AUTOSAR XML (schema 00044)
package /E40_Platform_System_SystemPackage/Components
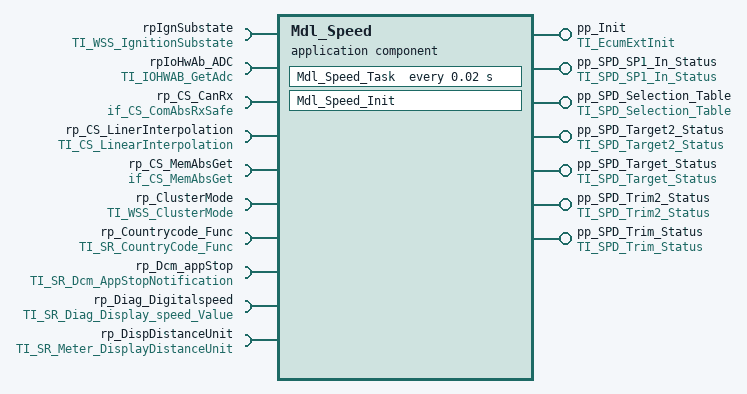
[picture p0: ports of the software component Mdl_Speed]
  application sw component type Mdl_Speed
    7 x provide port:
      pp_Init: server-com-spec{operation=Init, queue-length=1}, provided-interface=TI_EcumExtInit
      pp_SPD_SP1_In_Status: nonqueued-sender-com-spec{data-element=SP1_In_Status, init-value=constant-reference=Mdl_SpeedSP1_In_StatusValue0}, provided-interface=TI_SPD_SP1_In_Status
      pp_SPD_Selection_Table: nonqueued-sender-com-spec{data-element=Speed_Selection_Table, init-value=constant-reference=Mdl_SpeedSpeed_Selection_TableValue0}, provided-interface=TI_SPD_Selection_Table
      pp_SPD_Target2_Status: nonqueued-sender-com-spec{data-element=Spd_Target2_Status, init-value=constant-reference=Mdl_SpeedSpd_Target2_StatusValue0}, provided-interface=TI_SPD_Target2_Status
      pp_SPD_Target_Status: nonqueued-sender-com-spec{data-element=Spd_Target_Status, init-value=constant-reference=Mdl_SpeedSpd_Target_StatusValue0}, provided-interface=TI_SPD_Target_Status
      pp_SPD_Trim2_Status: nonqueued-sender-com-spec{data-element=Spd_Trim2_Status, init-value=constant-reference=Mdl_SpeedSpd_Trim2_StatusValue0}, provided-interface=TI_SPD_Trim2_Status
      pp_SPD_Trim_Status: nonqueued-sender-com-spec{data-element=Spd_Trim_Status, init-value=constant-reference=Mdl_SpeedSpd_Trim_StatusValue0}, provided-interface=TI_SPD_Trim_Status
    10 x require port:
      rpIgnSubstate: nonqueued-receiver-com-spec{data-element=IgnitionSubstate, init-value=constant-reference=Mdl_SpeedIgnitionSubstateValue0}, required-interface=TI_WSS_IgnitionSubstate
      rpIoHwAb_ADC: required-com-specs=[GetAsyncRawAdc, GetProcessedAdc, GetSyncRawAdc], required-interface=TI_IOHWAB_GetAdc
      rp_CS_CanRx: required-interface=if_CS_ComAbsRxSafe
        required-com-specs:
          RxCan_GetSignalValue
          RxCan_GetSignalValueU8Arr
          RxCan_SetSignalInitValue
          RxCan_SetSignalInitValueU8Arr
          RxCan_SignalClearJustRcvdStatus
          RxCan_SignalGetJustRcvdStatus
          RxCan_SignalInvalidProcessingControl
          RxCan_SignalMissingProcessingControl
          RxCan_SignalNRProcessingControl
      rp_CS_LinerInterpolation: required-interface=TI_CS_LinearInterpolation
        required-com-specs:
          Get_LinearInterpolateByte
          Get_LinearInterpolateSByte
          Get_LinearInterpolateSWord
          Get_LinearInterpolateWord
      rp_CS_MemAbsGet: required-interface=if_CS_MemAbsGet
        required-com-specs:
          Get_BsConst_Audio_Element
          Get_BsConst_Communication_Element
          Get_BsConst_EngOffTimer_Element
          Get_BsConst_FuelGauge_Element
          Get_BsConst_OilGauge_Element
          Get_BsConst_PowerGauge_Element
          Get_BsConst_Power_Element
          Get_BsConst_RealTimeClock_Element
          Get_BsConst_ServiceReminder_Element
          Get_BsConst_SpeedoGauge_Element
          Get_BsConst_TachoGauge_Element
          Get_BsConst_TempGauge_Element
          Get_BsConst_TripComputer_Element
          Get_BsConst_Warning_Element
          Get_BsCys_Certicificate_Element
          Get_BsDiag_Dtc_Element
          Get_BsDiag_ErrorRecord_Element
          Get_BsReten_Audio_Element
          Get_BsReten_Communication_Element
          Get_BsReten_Display_Element
          Get_BsReten_Gauges_Element
          Get_BsReten_Illumination_Element
          Get_BsReten_Odometer_Element
          Get_BsReten_Personalization_Element
          Get_BsReten_Power_Element
          Get_BsReten_RealTimeClock_Element
          Get_BsReten_Tripcomputer_Element
          Get_BsReten_Warning_Element
          Get_BsRt_CusDlt_Element
          Get_BsRt_FuelGauge_Element
          Get_BsRt_Illumination_Element
          Get_BsRt_Odometer_Element
          Get_BsRt_OilGauge_Element
          Get_BsRt_Personalization_Element
          Get_BsRt_PowerGauge_Element
          Get_BsRt_RealTimeClock_Element
          Get_BsRt_SpeedoGauge_Element
          Get_BsRt_TachoGauge_Element
          Get_BsRt_TempGauge_Element
          Get_BsRt_TripComputer_Element
          Get_BsRt_Warning_Element
          Get_BsShare_EcuPartNumber_Element
          Get_BsShare_SwUpdFotaFinPrint_Element
          Get_BsShare_SwUpdFotaMode_Element
          Get_BsShare_SwUpdFotaStatus_Element
          Get_BsShare_SwUpdFotadecrypt_Element
          Get_BsShare_SwUpdReflash_Element
          Get_BsShare_VehicleConfig_Element
          Get_BsShare_VisMeet_Element
          Get_RefCys_Certicificate1_Element
          Get_RefCys_Certicificate_Element
          Get_BsShare_VisMeet_EOLEntry_Element
          Get_BsShare_AssemblyManufacturingDate
          Get_BsShare_AssemblyPlantNumber
          Get_BsShare_HWModification
          Get_BsShare_PCBSerialNumber
          Get_BsShare_ProductSerialNumber
          Get_BsShare_SMTManufacturingDate
          Get_BsShare_SMTPlantNumber
          Get_BsShare_VisteonPCBPartNumber
          Get_BsShare_VisteonPartNumber
          Get_BsConst_Temperature_Sensor_Conv_SafeCopy2
          Get_BsConst_Temperature_Sensor_Conv_SafeCopy1
          Get_BsConst_Temperature_Sensor_Conv
          Get_BsConst_Temp_Threshold_Hysteresis_Derating_SafeCopy2
          Get_BsConst_Temp_Threshold_Hysteresis_Derating_SafeCopy1
          Get_BsConst_Temp_Threshold_Hysteresis_Derating
          Get_BsConst_PWM_boost_bypass_duty_SafeCopy2
          Get_BsConst_PWM_boost_bypass_duty_SafeCopy1
          Get_BsConst_PWM_boost_bypass_duty
          Get_BsConst_PCB_Temperature_Sensor_Conv_SafeCopy2
          Get_BsConst_PCB_Temperature_Sensor_Conv_SafeCopy1
          Get_BsConst_PCB_Temperature_Sensor_Conv
          Get_BsConst_Lookup_Curve_HotSpot_Coef_Y_SafeCopy2
          Get_BsConst_Lookup_Curve_HotSpot_Coef_Y_SafeCopy1
          Get_BsConst_Lookup_Curve_HotSpot_Coef_Y
          Get_BsConst_Lookup_Curve_HotSpot_Coef_X_SafeCopy2
          Get_BsConst_Lookup_Curve_HotSpot_Coef_X_SafeCopy1
          Get_BsConst_Lookup_Curve_HotSpot_Coef_X
          Get_BsConst_Display_Illum_Max_Level_SafeCopy2
          Get_BsConst_Display_Illum_Max_Level_SafeCopy1
          Get_BsConst_Display_Illum_Max_Level
          Get_BsConst_Derating_Backlight_Disable_SafeCopy2
          Get_BsConst_Derating_Backlight_Disable_SafeCopy1
          Get_BsConst_Derating_Backlight_Disable
          Get_BsConst_Compensation_Line_Slope_m_SafeCopy2
          Get_BsConst_Compensation_Line_Slope_m_SafeCopy1
          Get_BsConst_Compensation_Line_Slope_m
          Get_BsConst_Compensation_Line_Shift_b_SafeCopy2
          Get_BsConst_Compensation_Line_Shift_b_SafeCopy1
          Get_BsConst_Compensation_Line_Shift_b
          Get_BsConst_BsConst_Illumination_ReservedByte_SafeCopy2
          Get_BsConst_BsConst_Illumination_ReservedByte_SafeCopy1
          Get_BsConst_BsConst_Illumination_ReservedByte
      rp_ClusterMode: nonqueued-receiver-com-spec{data-element=WSSCurrentClusterMode, init-value=constant-reference=Mdl_SpeedWSSCurrentClusterModeValue0}, required-interface=TI_WSS_ClusterMode
      rp_Countrycode_Func: nonqueued-receiver-com-spec{data-element=CountryCode_Func, init-value=constant-reference=Mdl_SpeedCountryCode_FuncValue0}, required-interface=TI_SR_CountryCode_Func
      rp_Dcm_appStop: nonqueued-receiver-com-spec{data-element=AppId, init-value=constant-reference=Mdl_SpeedAppIdValue0}, required-interface=TI_SR_Dcm_AppStopNotification
      rp_Diag_Digitalspeed: nonqueued-receiver-com-spec{data-element=Diag_Digital_Speed_Value, init-value=constant-reference=Mdl_SpeedDiag_Digital_Speed_ValueValue0}, required-interface=TI_SR_Diag_Display_speed_Value
      rp_DispDistanceUnit: nonqueued-receiver-com-spec{data-element=DisplayUnit, init-value=constant-reference=Mdl_SpeedDisplayUnitValue0}, required-interface=TI_SR_Meter_DisplayDistanceUnit
    behavior IB_Mdl_Speed
      operation invoked event OIE_pp_Init_Mdl_Speed_InitTrigByInit: start-on-event=Mdl_Speed_Init, operation=pp_Init.Init
      timing event TEMdl_Speed_Task: start-on-event=Mdl_Speed_Task, period=0.02
      port-api-options:
        enable-take-address=false, indirect-api=false, port=pp_Init
        enable-take-address=false, indirect-api=false, port=pp_SPD_SP1_In_Status
        enable-take-address=false, indirect-api=false, port=pp_SPD_Selection_Table
        enable-take-address=false, indirect-api=false, port=pp_SPD_Target2_Status
        enable-take-address=false, indirect-api=false, port=pp_SPD_Target_Status
        enable-take-address=false, indirect-api=false, port=pp_SPD_Trim2_Status
        enable-take-address=false, indirect-api=false, port=pp_SPD_Trim_Status
        enable-take-address=false, indirect-api=false, port=rpIgnSubstate
        enable-take-address=false, indirect-api=false, port=rpIoHwAb_ADC
        enable-take-address=false, indirect-api=false, port=rp_CS_CanRx
        enable-take-address=false, indirect-api=false, port=rp_CS_LinerInterpolation
        enable-take-address=false, indirect-api=false, port=rp_CS_MemAbsGet
        enable-take-address=false, indirect-api=false, port=rp_ClusterMode
        enable-take-address=false, indirect-api=false, port=rp_Countrycode_Func
        enable-take-address=false, indirect-api=false, port=rp_Dcm_appStop
        enable-take-address=false, indirect-api=false, port=rp_Diag_Digitalspeed
        enable-take-address=false, indirect-api=false, port=rp_DispDistanceUnit
      runnable Mdl_Speed_Init: can-be-invoked-concurrently=true
      runnable Mdl_Speed_Task: can-be-invoked-concurrently=true
        data-receive-point-by-arguments:
          6 x access:
            DRA_rpIgnSubstate_IgnitionSubstate: accessed-variable=rpIgnSubstate.IgnitionSubstate
            DRA_rp_ClusterMode_WSSCurrentClusterMode: accessed-variable=rp_ClusterMode.WSSCurrentClusterMode
            DRA_rp_Countrycode_Func_CountryCode_Func: accessed-variable=rp_Countrycode_Func.CountryCode_Func
            DRA_rp_Dcm_appStop_AppId: accessed-variable=rp_Dcm_appStop.AppId
            DRA_rp_Diag_Digitalspeed_Diag_Digital_Speed_Value: accessed-variable=rp_Diag_Digitalspeed.Diag_Digital_Speed_Value
            DRA_rp_DispDistanceUnit_DisplayUnit: accessed-variable=rp_DispDistanceUnit.DisplayUnit
        data-send-points:
          6 x access:
            DWA_pp_SPD_SP1_In_Status_SP1_In_Status: accessed-variable=pp_SPD_SP1_In_Status.SP1_In_Status
            DWA_pp_SPD_Selection_Table_Speed_Selection_Table: accessed-variable=pp_SPD_Selection_Table.Speed_Selection_Table
            DWA_pp_SPD_Target2_Status_Spd_Target2_Status: accessed-variable=pp_SPD_Target2_Status.Spd_Target2_Status
            DWA_pp_SPD_Target_Status_Spd_Target_Status: accessed-variable=pp_SPD_Target_Status.Spd_Target_Status
            DWA_pp_SPD_Trim2_Status_Spd_Trim2_Status: accessed-variable=pp_SPD_Trim2_Status.Spd_Trim2_Status
            DWA_pp_SPD_Trim_Status_Spd_Trim_Status: accessed-variable=pp_SPD_Trim_Status.Spd_Trim_Status
        110 x sync call:
          OA_rpIoHwAb_ADC_GetAsyncRawAdc: operation=rpIoHwAb_ADC.GetAsyncRawAdc
          OA_rpIoHwAb_ADC_GetSyncRawAdc: operation=rpIoHwAb_ADC.GetSyncRawAdc
          OA_rpIoHwAb_ADC_GetProcessedAdc: operation=rpIoHwAb_ADC.GetProcessedAdc
          OA_rp_CS_CanRx_RxCan_GetSignalValueU8Arr: operation=rp_CS_CanRx.RxCan_GetSignalValueU8Arr
          OA_rp_CS_CanRx_RxCan_SetSignalInitValue: operation=rp_CS_CanRx.RxCan_SetSignalInitValue
          OA_rp_CS_CanRx_RxCan_SetSignalInitValueU8Arr: operation=rp_CS_CanRx.RxCan_SetSignalInitValueU8Arr
          OA_rp_CS_CanRx_RxCan_SignalInvalidProcessingControl: operation=rp_CS_CanRx.RxCan_SignalInvalidProcessingControl
          OA_rp_CS_CanRx_RxCan_SignalMissingProcessingControl: operation=rp_CS_CanRx.RxCan_SignalMissingProcessingControl
          OA_rp_CS_CanRx_RxCan_SignalNRProcessingControl: operation=rp_CS_CanRx.RxCan_SignalNRProcessingControl
          OA_rp_CS_CanRx_RxCan_SignalGetJustRcvdStatus: operation=rp_CS_CanRx.RxCan_SignalGetJustRcvdStatus
          OA_rp_CS_CanRx_RxCan_SignalClearJustRcvdStatus: operation=rp_CS_CanRx.RxCan_SignalClearJustRcvdStatus
          OA_rp_CS_CanRx_RxCan_GetSignalValue: operation=rp_CS_CanRx.RxCan_GetSignalValue
          OA_rp_CS_LinerInterpolation_Get_LinearInterpolateWord: operation=rp_CS_LinerInterpolation.Get_LinearInterpolateWord
          OA_rp_CS_LinerInterpolation_Get_LinearInterpolateByte: operation=rp_CS_LinerInterpolation.Get_LinearInterpolateByte
          OA_rp_CS_LinerInterpolation_Get_LinearInterpolateSByte: operation=rp_CS_LinerInterpolation.Get_LinearInterpolateSByte
          OA_rp_CS_LinerInterpolation_Get_LinearInterpolateSWord: operation=rp_CS_LinerInterpolation.Get_LinearInterpolateSWord
          OA_rp_CS_MemAbsGet_Get_BsShare_SwUpdReflash_Element: operation=rp_CS_MemAbsGet.Get_BsShare_SwUpdReflash_Element
          OA_rp_CS_MemAbsGet_Get_BsShare_SwUpdFotaMode_Element: operation=rp_CS_MemAbsGet.Get_BsShare_SwUpdFotaMode_Element
          OA_rp_CS_MemAbsGet_Get_BsShare_SwUpdFotaFinPrint_Element: operation=rp_CS_MemAbsGet.Get_BsShare_SwUpdFotaFinPrint_Element
          OA_rp_CS_MemAbsGet_Get_BsShare_SwUpdFotaStatus_Element: operation=rp_CS_MemAbsGet.Get_BsShare_SwUpdFotaStatus_Element
          OA_rp_CS_MemAbsGet_Get_BsShare_SwUpdFotadecrypt_Element: operation=rp_CS_MemAbsGet.Get_BsShare_SwUpdFotadecrypt_Element
          OA_rp_CS_MemAbsGet_Get_BsShare_EcuPartNumber_Element: operation=rp_CS_MemAbsGet.Get_BsShare_EcuPartNumber_Element
          OA_rp_CS_MemAbsGet_Get_BsShare_VisteonPartNumber: operation=rp_CS_MemAbsGet.Get_BsShare_VisteonPartNumber
          OA_rp_CS_MemAbsGet_Get_BsShare_VisteonPCBPartNumber: operation=rp_CS_MemAbsGet.Get_BsShare_VisteonPCBPartNumber
          OA_rp_CS_MemAbsGet_Get_BsShare_ProductSerialNumber: operation=rp_CS_MemAbsGet.Get_BsShare_ProductSerialNumber
          OA_rp_CS_MemAbsGet_Get_BsShare_PCBSerialNumber: operation=rp_CS_MemAbsGet.Get_BsShare_PCBSerialNumber
          OA_rp_CS_MemAbsGet_Get_BsShare_SMTManufacturingDate: operation=rp_CS_MemAbsGet.Get_BsShare_SMTManufacturingDate
          OA_rp_CS_MemAbsGet_Get_BsShare_AssemblyManufacturingDate: operation=rp_CS_MemAbsGet.Get_BsShare_AssemblyManufacturingDate
          OA_rp_CS_MemAbsGet_Get_BsShare_SMTPlantNumber: operation=rp_CS_MemAbsGet.Get_BsShare_SMTPlantNumber
          OA_rp_CS_MemAbsGet_Get_BsShare_AssemblyPlantNumber: operation=rp_CS_MemAbsGet.Get_BsShare_AssemblyPlantNumber
          OA_rp_CS_MemAbsGet_Get_BsShare_HWModification: operation=rp_CS_MemAbsGet.Get_BsShare_HWModification
          OA_rp_CS_MemAbsGet_Get_BsShare_VisMeet_Element: operation=rp_CS_MemAbsGet.Get_BsShare_VisMeet_Element
          OA_rp_CS_MemAbsGet_Get_BsShare_VisMeet_EOLEntry_Element: operation=rp_CS_MemAbsGet.Get_BsShare_VisMeet_EOLEntry_Element
          OA_rp_CS_MemAbsGet_Get_BsShare_VehicleConfig_Element: operation=rp_CS_MemAbsGet.Get_BsShare_VehicleConfig_Element
          OA_rp_CS_MemAbsGet_Get_BsConst_SpeedoGauge_Element: operation=rp_CS_MemAbsGet.Get_BsConst_SpeedoGauge_Element
          OA_rp_CS_MemAbsGet_Get_BsConst_TachoGauge_Element: operation=rp_CS_MemAbsGet.Get_BsConst_TachoGauge_Element
          OA_rp_CS_MemAbsGet_Get_BsConst_FuelGauge_Element: operation=rp_CS_MemAbsGet.Get_BsConst_FuelGauge_Element
          OA_rp_CS_MemAbsGet_Get_BsConst_TempGauge_Element: operation=rp_CS_MemAbsGet.Get_BsConst_TempGauge_Element
          OA_rp_CS_MemAbsGet_Get_BsConst_PowerGauge_Element: operation=rp_CS_MemAbsGet.Get_BsConst_PowerGauge_Element
          OA_rp_CS_MemAbsGet_Get_BsConst_OilGauge_Element: operation=rp_CS_MemAbsGet.Get_BsConst_OilGauge_Element
          OA_rp_CS_MemAbsGet_Get_BsConst_TripComputer_Element: operation=rp_CS_MemAbsGet.Get_BsConst_TripComputer_Element
          OA_rp_CS_MemAbsGet_Get_BsConst_Audio_Element: operation=rp_CS_MemAbsGet.Get_BsConst_Audio_Element
          OA_rp_CS_MemAbsGet_Get_BsConst_Warning_Element: operation=rp_CS_MemAbsGet.Get_BsConst_Warning_Element
          OA_rp_CS_MemAbsGet_Get_BsConst_RealTimeClock_Element: operation=rp_CS_MemAbsGet.Get_BsConst_RealTimeClock_Element
          OA_rp_CS_MemAbsGet_Get_BsConst_Communication_Element: operation=rp_CS_MemAbsGet.Get_BsConst_Communication_Element
          OA_rp_CS_MemAbsGet_Get_BsConst_Power_Element: operation=rp_CS_MemAbsGet.Get_BsConst_Power_Element
          OA_rp_CS_MemAbsGet_Get_BsConst_ServiceReminder_Element: operation=rp_CS_MemAbsGet.Get_BsConst_ServiceReminder_Element
          OA_rp_CS_MemAbsGet_Get_BsConst_EngOffTimer_Element: operation=rp_CS_MemAbsGet.Get_BsConst_EngOffTimer_Element
          OA_rp_CS_MemAbsGet_Get_BsCys_Certicificate_Element: operation=rp_CS_MemAbsGet.Get_BsCys_Certicificate_Element
          OA_rp_CS_MemAbsGet_Get_RefCys_Certicificate_Element: operation=rp_CS_MemAbsGet.Get_RefCys_Certicificate_Element
          OA_rp_CS_MemAbsGet_Get_RefCys_Certicificate1_Element: operation=rp_CS_MemAbsGet.Get_RefCys_Certicificate1_Element
          OA_rp_CS_MemAbsGet_Get_BsRt_Odometer_Element: operation=rp_CS_MemAbsGet.Get_BsRt_Odometer_Element
          OA_rp_CS_MemAbsGet_Get_BsRt_SpeedoGauge_Element: operation=rp_CS_MemAbsGet.Get_BsRt_SpeedoGauge_Element
          OA_rp_CS_MemAbsGet_Get_BsRt_TachoGauge_Element: operation=rp_CS_MemAbsGet.Get_BsRt_TachoGauge_Element
          OA_rp_CS_MemAbsGet_Get_BsRt_FuelGauge_Element: operation=rp_CS_MemAbsGet.Get_BsRt_FuelGauge_Element
          OA_rp_CS_MemAbsGet_Get_BsRt_TempGauge_Element: operation=rp_CS_MemAbsGet.Get_BsRt_TempGauge_Element
          OA_rp_CS_MemAbsGet_Get_BsRt_PowerGauge_Element: operation=rp_CS_MemAbsGet.Get_BsRt_PowerGauge_Element
          OA_rp_CS_MemAbsGet_Get_BsRt_OilGauge_Element: operation=rp_CS_MemAbsGet.Get_BsRt_OilGauge_Element
          OA_rp_CS_MemAbsGet_Get_BsRt_TripComputer_Element: operation=rp_CS_MemAbsGet.Get_BsRt_TripComputer_Element
          OA_rp_CS_MemAbsGet_Get_BsRt_Warning_Element: operation=rp_CS_MemAbsGet.Get_BsRt_Warning_Element
          OA_rp_CS_MemAbsGet_Get_BsRt_RealTimeClock_Element: operation=rp_CS_MemAbsGet.Get_BsRt_RealTimeClock_Element
          OA_rp_CS_MemAbsGet_Get_BsRt_Personalization_Element: operation=rp_CS_MemAbsGet.Get_BsRt_Personalization_Element
          OA_rp_CS_MemAbsGet_Get_BsRt_Illumination_Element: operation=rp_CS_MemAbsGet.Get_BsRt_Illumination_Element
          OA_rp_CS_MemAbsGet_Get_BsRt_CusDlt_Element: operation=rp_CS_MemAbsGet.Get_BsRt_CusDlt_Element
          OA_rp_CS_MemAbsGet_Get_BsReten_Odometer_Element: operation=rp_CS_MemAbsGet.Get_BsReten_Odometer_Element
          OA_rp_CS_MemAbsGet_Get_BsReten_Gauges_Element: operation=rp_CS_MemAbsGet.Get_BsReten_Gauges_Element
          OA_rp_CS_MemAbsGet_Get_BsReten_Tripcomputer_Element: operation=rp_CS_MemAbsGet.Get_BsReten_Tripcomputer_Element
          OA_rp_CS_MemAbsGet_Get_BsReten_Illumination_Element: operation=rp_CS_MemAbsGet.Get_BsReten_Illumination_Element
          OA_rp_CS_MemAbsGet_Get_BsReten_Audio_Element: operation=rp_CS_MemAbsGet.Get_BsReten_Audio_Element
          OA_rp_CS_MemAbsGet_Get_BsReten_Warning_Element: operation=rp_CS_MemAbsGet.Get_BsReten_Warning_Element
          OA_rp_CS_MemAbsGet_Get_BsReten_RealTimeClock_Element: operation=rp_CS_MemAbsGet.Get_BsReten_RealTimeClock_Element
          OA_rp_CS_MemAbsGet_Get_BsReten_Communication_Element: operation=rp_CS_MemAbsGet.Get_BsReten_Communication_Element
          OA_rp_CS_MemAbsGet_Get_BsReten_Personalization_Element: operation=rp_CS_MemAbsGet.Get_BsReten_Personalization_Element
          OA_rp_CS_MemAbsGet_Get_BsReten_Power_Element: operation=rp_CS_MemAbsGet.Get_BsReten_Power_Element
          OA_rp_CS_MemAbsGet_Get_BsReten_Display_Element: operation=rp_CS_MemAbsGet.Get_BsReten_Display_Element
          OA_rp_CS_MemAbsGet_Get_BsDiag_ErrorRecord_Element: operation=rp_CS_MemAbsGet.Get_BsDiag_ErrorRecord_Element
          OA_rp_CS_MemAbsGet_Get_BsDiag_Dtc_Element: operation=rp_CS_MemAbsGet.Get_BsDiag_Dtc_Element
          OA_rp_CS_MemAbsGet_Get_BsConst_Compensation_Line_Slope_m: operation=rp_CS_MemAbsGet.Get_BsConst_Compensation_Line_Slope_m
          OA_rp_CS_MemAbsGet_Get_BsConst_Compensation_Line_Shift_b: operation=rp_CS_MemAbsGet.Get_BsConst_Compensation_Line_Shift_b
          OA_rp_CS_MemAbsGet_Get_BsConst_Lookup_Curve_HotSpot_Coef_X: operation=rp_CS_MemAbsGet.Get_BsConst_Lookup_Curve_HotSpot_Coef_X
          OA_rp_CS_MemAbsGet_Get_BsConst_Lookup_Curve_HotSpot_Coef_Y: operation=rp_CS_MemAbsGet.Get_BsConst_Lookup_Curve_HotSpot_Coef_Y
          OA_rp_CS_MemAbsGet_Get_BsConst_Temp_Threshold_Hysteresis_Derating: operation=rp_CS_MemAbsGet.Get_BsConst_Temp_Threshold_Hysteresis_Derating
          OA_rp_CS_MemAbsGet_Get_BsConst_Derating_Backlight_Disable: operation=rp_CS_MemAbsGet.Get_BsConst_Derating_Backlight_Disable
          OA_rp_CS_MemAbsGet_Get_BsConst_Temperature_Sensor_Conv: operation=rp_CS_MemAbsGet.Get_BsConst_Temperature_Sensor_Conv
          OA_rp_CS_MemAbsGet_Get_BsConst_PCB_Temperature_Sensor_Conv: operation=rp_CS_MemAbsGet.Get_BsConst_PCB_Temperature_Sensor_Conv
          OA_rp_CS_MemAbsGet_Get_BsConst_Display_Illum_Max_Level: operation=rp_CS_MemAbsGet.Get_BsConst_Display_Illum_Max_Level
          OA_rp_CS_MemAbsGet_Get_BsConst_PWM_boost_bypass_duty: operation=rp_CS_MemAbsGet.Get_BsConst_PWM_boost_bypass_duty
          OA_rp_CS_MemAbsGet_Get_BsConst_BsConst_Illumination_ReservedByte: operation=rp_CS_MemAbsGet.Get_BsConst_BsConst_Illumination_ReservedByte
          OA_rp_CS_MemAbsGet_Get_BsConst_Compensation_Line_Slope_m_SafeCopy1: operation=rp_CS_MemAbsGet.Get_BsConst_Compensation_Line_Slope_m_SafeCopy1
          OA_rp_CS_MemAbsGet_Get_BsConst_Compensation_Line_Shift_b_SafeCopy1: operation=rp_CS_MemAbsGet.Get_BsConst_Compensation_Line_Shift_b_SafeCopy1
          OA_rp_CS_MemAbsGet_Get_BsConst_Lookup_Curve_HotSpot_Coef_X_SafeCopy1: operation=rp_CS_MemAbsGet.Get_BsConst_Lookup_Curve_HotSpot_Coef_X_SafeCopy1
          OA_rp_CS_MemAbsGet_Get_BsConst_Lookup_Curve_HotSpot_Coef_Y_SafeCopy1: operation=rp_CS_MemAbsGet.Get_BsConst_Lookup_Curve_HotSpot_Coef_Y_SafeCopy1
          OA_rp_CS_MemAbsGet_Get_BsConst_Temp_Threshold_Hysteresis_Derating_SafeCopy1: operation=rp_CS_MemAbsGet.Get_BsConst_Temp_Threshold_Hysteresis_Derating_SafeCopy1
          OA_rp_CS_MemAbsGet_Get_BsConst_Derating_Backlight_Disable_SafeCopy1: operation=rp_CS_MemAbsGet.Get_BsConst_Derating_Backlight_Disable_SafeCopy1
          OA_rp_CS_MemAbsGet_Get_BsConst_Temperature_Sensor_Conv_SafeCopy1: operation=rp_CS_MemAbsGet.Get_BsConst_Temperature_Sensor_Conv_SafeCopy1
          OA_rp_CS_MemAbsGet_Get_BsConst_PCB_Temperature_Sensor_Conv_SafeCopy1: operation=rp_CS_MemAbsGet.Get_BsConst_PCB_Temperature_Sensor_Conv_SafeCopy1
          OA_rp_CS_MemAbsGet_Get_BsConst_Display_Illum_Max_Level_SafeCopy1: operation=rp_CS_MemAbsGet.Get_BsConst_Display_Illum_Max_Level_SafeCopy1
          OA_rp_CS_MemAbsGet_Get_BsConst_PWM_boost_bypass_duty_SafeCopy1: operation=rp_CS_MemAbsGet.Get_BsConst_PWM_boost_bypass_duty_SafeCopy1
          OA_rp_CS_MemAbsGet_Get_BsConst_BsConst_Illumination_ReservedByte_SafeCopy1: operation=rp_CS_MemAbsGet.Get_BsConst_BsConst_Illumination_ReservedByte_SafeCopy1
          OA_rp_CS_MemAbsGet_Get_BsConst_Compensation_Line_Slope_m_SafeCopy2: operation=rp_CS_MemAbsGet.Get_BsConst_Compensation_Line_Slope_m_SafeCopy2
          OA_rp_CS_MemAbsGet_Get_BsConst_Compensation_Line_Shift_b_SafeCopy2: operation=rp_CS_MemAbsGet.Get_BsConst_Compensation_Line_Shift_b_SafeCopy2
          OA_rp_CS_MemAbsGet_Get_BsConst_Lookup_Curve_HotSpot_Coef_X_SafeCopy2: operation=rp_CS_MemAbsGet.Get_BsConst_Lookup_Curve_HotSpot_Coef_X_SafeCopy2
          OA_rp_CS_MemAbsGet_Get_BsConst_Lookup_Curve_HotSpot_Coef_Y_SafeCopy2: operation=rp_CS_MemAbsGet.Get_BsConst_Lookup_Curve_HotSpot_Coef_Y_SafeCopy2
          OA_rp_CS_MemAbsGet_Get_BsConst_Temp_Threshold_Hysteresis_Derating_SafeCopy2: operation=rp_CS_MemAbsGet.Get_BsConst_Temp_Threshold_Hysteresis_Derating_SafeCopy2
          OA_rp_CS_MemAbsGet_Get_BsConst_Derating_Backlight_Disable_SafeCopy2: operation=rp_CS_MemAbsGet.Get_BsConst_Derating_Backlight_Disable_SafeCopy2
          OA_rp_CS_MemAbsGet_Get_BsConst_Temperature_Sensor_Conv_SafeCopy2: operation=rp_CS_MemAbsGet.Get_BsConst_Temperature_Sensor_Conv_SafeCopy2
          OA_rp_CS_MemAbsGet_Get_BsConst_PCB_Temperature_Sensor_Conv_SafeCopy2: operation=rp_CS_MemAbsGet.Get_BsConst_PCB_Temperature_Sensor_Conv_SafeCopy2
          OA_rp_CS_MemAbsGet_Get_BsConst_Display_Illum_Max_Level_SafeCopy2: operation=rp_CS_MemAbsGet.Get_BsConst_Display_Illum_Max_Level_SafeCopy2
          OA_rp_CS_MemAbsGet_Get_BsConst_PWM_boost_bypass_duty_SafeCopy2: operation=rp_CS_MemAbsGet.Get_BsConst_PWM_boost_bypass_duty_SafeCopy2
          OA_rp_CS_MemAbsGet_Get_BsConst_BsConst_Illumination_ReservedByte_SafeCopy2: operation=rp_CS_MemAbsGet.Get_BsConst_BsConst_Illumination_ReservedByte_SafeCopy2
  swc implementation IMPL_Mdl_Speed: behavior=IB_Mdl_Speed
